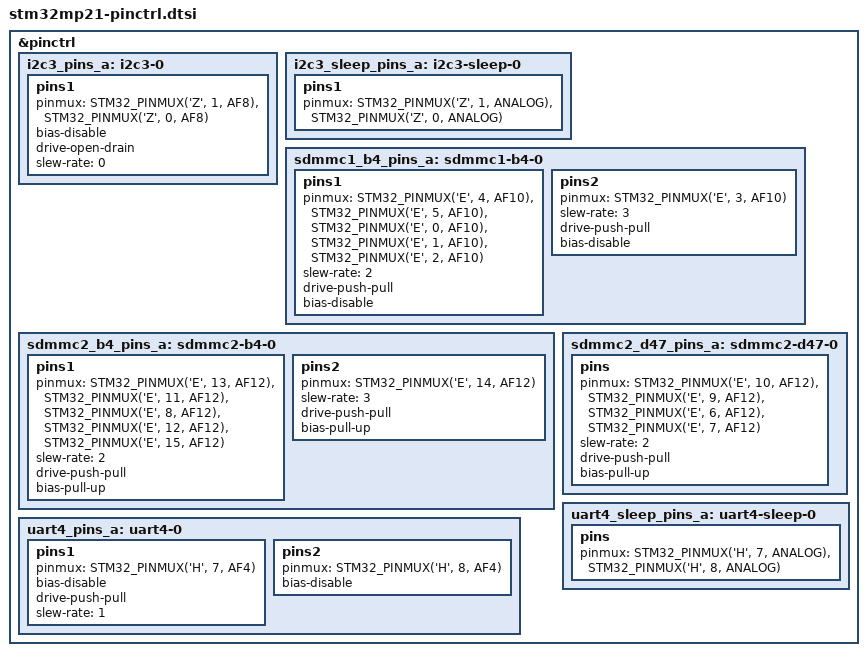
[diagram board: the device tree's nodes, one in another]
/*
 * Copyright (c) 2026, STMicroelectronics - All Rights Reserved
 *
 * SPDX-License-Identifier: Apache-2.0
 */
#include <dt-bindings/pinctrl/stm32-pinfunc.h>

&pinctrl {
	i2c3_pins_a: i2c3-0 {
		pins1 {
			pinmux = <STM32_PINMUX('Z', 1, AF8)>, /* I2C3_SCL */
				 <STM32_PINMUX('Z', 0, AF8)>; /* I2C3_SDA */
			bias-disable;
			drive-open-drain;
			slew-rate = <0>;
		};
	};

	i2c3_sleep_pins_a: i2c3-sleep-0 {
		pins1 {
			pinmux = <STM32_PINMUX('Z', 1, ANALOG)>, /* I2C3_SCL */
				 <STM32_PINMUX('Z', 0, ANALOG)>; /* I2C3_SDA */
		};
	};

	sdmmc1_b4_pins_a: sdmmc1-b4-0 {
		pins1 {
			pinmux = <STM32_PINMUX('E', 4, AF10)>, /* SDMMC1_D0 */
				 <STM32_PINMUX('E', 5, AF10)>, /* SDMMC1_D1 */
				 <STM32_PINMUX('E', 0, AF10)>, /* SDMMC1_D2 */
				 <STM32_PINMUX('E', 1, AF10)>, /* SDMMC1_D3 */
				 <STM32_PINMUX('E', 2, AF10)>; /* SDMMC1_CMD */
			slew-rate = <2>;
			drive-push-pull;
			bias-disable;
		};
		pins2 {
			pinmux = <STM32_PINMUX('E', 3, AF10)>; /* SDMMC1_CK */
			slew-rate = <3>;
			drive-push-pull;
			bias-disable;
		};
	};

	sdmmc2_b4_pins_a: sdmmc2-b4-0 {
		pins1 {
			pinmux = <STM32_PINMUX('E', 13, AF12)>, /* SDMMC2_D0 */
				 <STM32_PINMUX('E', 11, AF12)>, /* SDMMC2_D1 */
				 <STM32_PINMUX('E', 8, AF12)>, /* SDMMC2_D2 */
				 <STM32_PINMUX('E', 12, AF12)>, /* SDMMC2_D3 */
				 <STM32_PINMUX('E', 15, AF12)>; /* SDMMC2_CMD */
			slew-rate = <2>;
			drive-push-pull;
			bias-pull-up;
		};
		pins2 {
			pinmux = <STM32_PINMUX('E', 14, AF12)>; /* SDMMC2_CK */
			slew-rate = <3>;
			drive-push-pull;
			bias-pull-up;
		};
	};

	sdmmc2_d47_pins_a: sdmmc2-d47-0 {
		pins {
			pinmux = <STM32_PINMUX('E', 10, AF12)>, /* SDMMC2_D4 */
				 <STM32_PINMUX('E', 9, AF12)>, /* SDMMC2_D5 */
				 <STM32_PINMUX('E', 6, AF12)>, /* SDMMC2_D6 */
				 <STM32_PINMUX('E', 7, AF12)>; /* SDMMC2_D7 */
			slew-rate = <2>;
			drive-push-pull;
			bias-pull-up;
		};
	};

	uart4_pins_a: uart4-0 {
		pins1 {
			pinmux = <STM32_PINMUX('H', 7, AF4)>; /* UART4_TX */
			bias-disable;
			drive-push-pull;
			slew-rate = <1>;
		};
		pins2 {
			pinmux = <STM32_PINMUX('H', 8, AF4)>; /* UART4_RX */
			bias-disable;
		};
	};

	uart4_sleep_pins_a: uart4-sleep-0 {
		pins {
			pinmux = <STM32_PINMUX('H', 7, ANALOG)>, /* UART4_TX */
				 <STM32_PINMUX('H', 8, ANALOG)>; /* UART4_RX */
		};
	};
};
